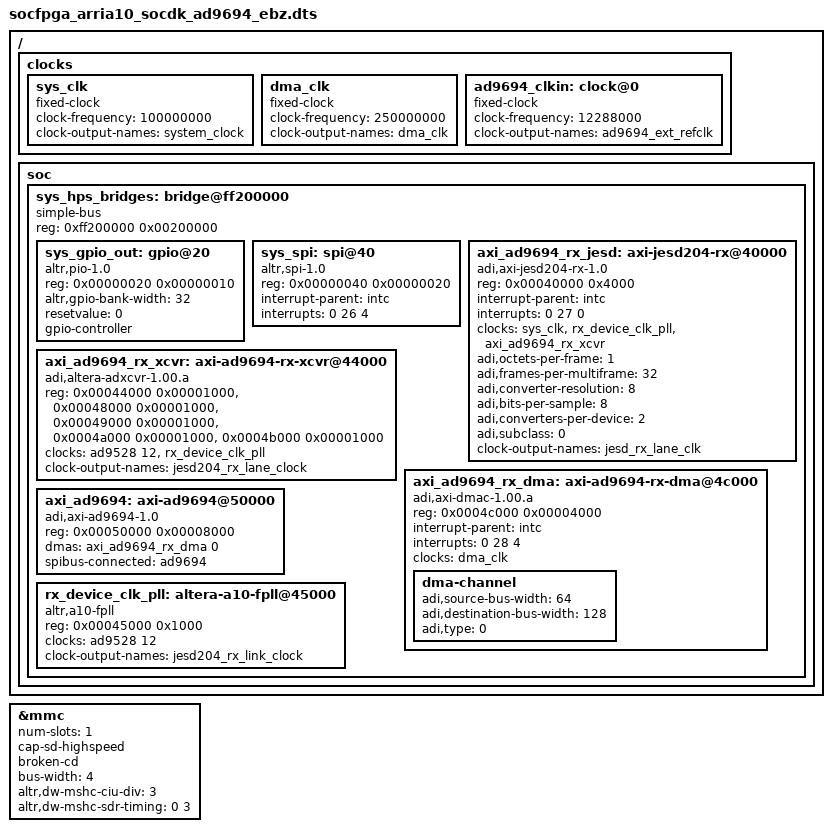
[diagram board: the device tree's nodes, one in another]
/dts-v1/;
#include "socfpga_arria10_socdk.dtsi"

&mmc {
	status = "okay";
	num-slots = <1>;
	cap-sd-highspeed;
	broken-cd;
	bus-width = <4>;
	altr,dw-mshc-ciu-div = <3>;
	altr,dw-mshc-sdr-timing = <0 3>;
};

/ {
	clocks {
		sys_clk: sys_clk {
			#clock-cells = <0>;
			compatible = "fixed-clock";
			clock-frequency = <100000000>;
			clock-output-names = "system_clock";
		};

		dma_clk: dma_clk {
			#clock-cells = <0x0>;
			compatible = "fixed-clock";
			clock-frequency = <250000000>;
			clock-output-names = "dma_clk";
		};
	};

	soc {
		sys_hps_bridges: bridge@ff200000 {
			compatible = "simple-bus";
			reg = <0xff200000 0x00200000>;
			#address-cells = <1>;
			#size-cells = <1>;
			ranges = <0x00000000 0xff200000 0x00200000>;

			sys_gpio_out: gpio@20 {
				compatible = "altr,pio-1.0";
				reg = <0x00000020 0x00000010>;
				altr,gpio-bank-width = <32>;
				resetvalue = <0>;
				#gpio-cells = <2>;
				gpio-controller;
			};

			sys_spi: spi@40 {
				compatible = "altr,spi-1.0";
				reg = <0x00000040 0x00000020>;
				interrupt-parent = <&intc>;
				interrupts = <0 26 4>;
				#address-cells = <0x1>;
				#size-cells = <0x0>;
			};

			axi_ad9694_rx_jesd: axi-jesd204-rx@40000 {
				compatible = "adi,axi-jesd204-rx-1.0";
				reg = <0x00040000 0x4000>;

				interrupt-parent = <&intc>;
				interrupts = <0 27 0>;

				clocks = <&sys_clk>, <&rx_device_clk_pll>, <&axi_ad9694_rx_xcvr>;
				clock-names = "s_axi_aclk", "device_clk", "lane_clk";

				adi,octets-per-frame = <1>;
				adi,frames-per-multiframe = <32>;
				adi,converter-resolution = <8>;
				adi,bits-per-sample = <8>;
				adi,converters-per-device = <2>;
				adi,subclass = <0>;

				#clock-cells = <0>;
				clock-output-names = "jesd_rx_lane_clk";
			};

			axi_ad9694_rx_xcvr: axi-ad9694-rx-xcvr@44000 {
				compatible = "adi,altera-adxcvr-1.00.a";
				reg = <0x00044000 0x00001000>,
					<0x00048000 0x00001000>,
					<0x00049000 0x00001000>,
					<0x0004a000 0x00001000>,
					<0x0004b000 0x00001000>;
				reg-names = "adxcvr", "adxcfg-0", "adxcfg-1", "adxcfg-2",
				"adxcfg-3";

				clocks = <&ad9528 12>, <&rx_device_clk_pll>;
				clock-names = "ref", "link";

				#clock-cells = <0>;
				clock-output-names = "jesd204_rx_lane_clock";
			};

			axi_ad9694_rx_dma: axi-ad9694-rx-dma@4c000 {
				compatible = "adi,axi-dmac-1.00.a";
				reg = <0x0004c000 0x00004000>;
				interrupt-parent = <&intc>;
				interrupts = <0 28 4>;
				#dma-cells = <1>;
				clocks = <&dma_clk>;

				dma-channel {
					adi,source-bus-width = <64>;
					adi,destination-bus-width = <128>;
					adi,type = <0>;
				};
			};

			axi_ad9694: axi-ad9694@50000 {
				compatible = "adi,axi-ad9694-1.0";
				reg = <0x00050000 0x00008000>;
				dmas = <&axi_ad9694_rx_dma 0>;
				dma-names = "rx";
				spibus-connected = <&ad9694>;
			};

			rx_device_clk_pll: altera-a10-fpll@45000 {
				compatible = "altr,a10-fpll";
				reg = <0x00045000 0x1000>;
				clocks = <&ad9528 12>;

				#clock-cells = <0>;
				clock-output-names = "jesd204_rx_link_clock";
			};
		};
	};
};

/ {
	clocks {
		ad9694_clkin: clock@0 {
			#clock-cells = <0>;
			compatible = "fixed-clock";
			clock-frequency = <12288000>;
			clock-output-names = "ad9694_ext_refclk";
		};
	};
};

#define fmc_spi sys_spi

#include "adi-ad9694-ebz.dtsi"
